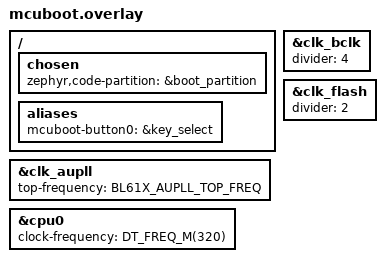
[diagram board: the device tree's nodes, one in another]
#include "../bootloader/partitions.dtsi"
/ {
	chosen {
		zephyr,code-partition = &boot_partition;
	};
	aliases {
		mcuboot-button0 = &key_select;
	};
};

/* Recovery prioritizes reliable flash reads over emulation clocks. */
&clk_aupll {
	top-frequency = <BL61X_AUPLL_TOP_FREQ>;
};

&clk_bclk {
	divider = <4>;
};

&clk_flash {
	divider = <2>;
};

&cpu0 {
	clock-frequency = <DT_FREQ_M(320)>;
};
